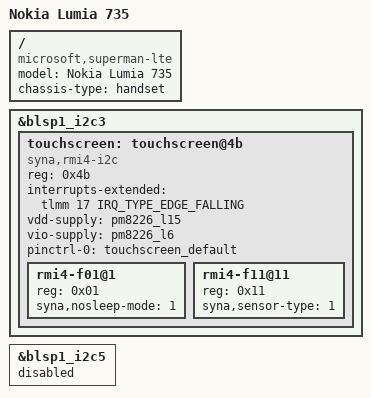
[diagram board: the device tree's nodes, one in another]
// SPDX-License-Identifier: BSD-3-Clause
/*
 * Copyright (c) 2023, Jack Matthews <jm5112356@gmail.com>
 * Copyright (c) 2023, Ivaylo Ivanov <ivo.ivanov.ivanov1@gmail.com>
 * Copyright (c) 2023, Dominik Kobinski <dominikkobinski314@gmail.com>
 * Copyright (c) 2023, Rayyan Ansari <rayyan@ansari.sh>
 */

/dts-v1/;

#include "msm8926.dtsi"
#include "qcom-msm8226-microsoft-common.dtsi"

/* This device has touchscreen on i2c3 instead */
/delete-node/ &touchscreen;

/ {
	model = "Nokia Lumia 735";
	compatible = "microsoft,superman-lte", "qcom,msm8926", "qcom,msm8226";
	chassis-type = "handset";
};

&blsp1_i2c3 {
	status = "okay";

	touchscreen: touchscreen@4b {
		compatible = "syna,rmi4-i2c";
		reg = <0x4b>;

		interrupts-extended = <&tlmm 17 IRQ_TYPE_EDGE_FALLING>;
		vdd-supply = <&pm8226_l15>;
		vio-supply = <&pm8226_l6>;

		pinctrl-0 = <&touchscreen_default>;
		pinctrl-names = "default";

		#address-cells = <1>;
		#size-cells = <0>;

		rmi4-f01@1 {
			reg = <0x01>;
			syna,nosleep-mode = <1>;
		};

		rmi4-f11@11 {
			reg = <0x11>;
			syna,sensor-type = <1>;
		};
	};
};

&blsp1_i2c5 {
	status = "disabled";
};
